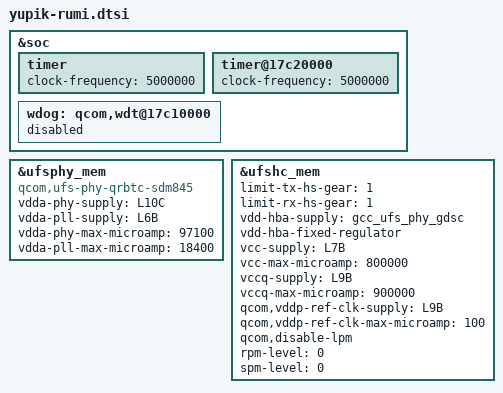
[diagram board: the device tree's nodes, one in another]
&soc {
	timer {
		clock-frequency = <5000000>;
	};

	timer@17c20000 {
		clock-frequency = <5000000>;
	};

	wdog: qcom,wdt@17c10000 {
		status = "disabled";
	};
};

&ufsphy_mem {
	compatible = "qcom,ufs-phy-qrbtc-sdm845";

	vdda-phy-supply = <&L10C>;
	vdda-pll-supply = <&L6B>;
	vdda-phy-max-microamp = <97100>;
	vdda-pll-max-microamp = <18400>;

	status = "ok";
};

&ufshc_mem {
	limit-tx-hs-gear = <1>;
	limit-rx-hs-gear = <1>;

	vdd-hba-supply = <&gcc_ufs_phy_gdsc>;
	vdd-hba-fixed-regulator;

	vcc-supply = <&L7B>;
	vcc-max-microamp = <800000>;

	vccq-supply = <&L9B>;
	vccq-max-microamp = <900000>;

	qcom,vddp-ref-clk-supply = <&L9B>;
	qcom,vddp-ref-clk-max-microamp = <100>;

	qcom,disable-lpm;
	rpm-level = <0>;
	spm-level = <0>;

	status = "ok";
};
